VERSION ""

NS_ :

BS_:

BU_:

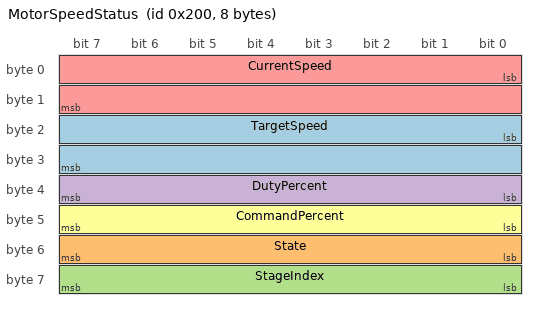
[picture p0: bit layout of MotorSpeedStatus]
BO_ 512 MotorSpeedStatus: 8 Vector__XXX
 SG_ TargetSpeed : 16|16@1+ (0.001,0) [0|0] "m/s" Vector__XXX
 SG_ State : 48|8@1+ (1,0) [0|0] "" Vector__XXX
 SG_ StageIndex : 56|8@1+ (1,0) [0|0] "" Vector__XXX
 SG_ DutyPercent : 32|8@1+ (1,0) [0|0] "%" Vector__XXX
 SG_ CurrentSpeed : 0|16@1+ (0.001,0) [0|0] "m/s" Vector__XXX
 SG_ CommandPercent : 40|8@1+ (1,0) [0|0] "%" Vector__XXX
